# PIC32CX2051BZ66048 register map
Vendor: Microchip Technology; Series: PIC32CXBZ66; File version: 0
CPU: CM4 r0p1, little endian, MPU, FPU, 3 interrupt priority bits, 58 interrupts
Registers are 32-bit, read-write, reset 0x0 unless marked. A register's access mark holds for its fields unless they carry their own. Offsets are from the block's base; [hi:lo] are bit positions; {n}, {i} and the like mark numbered series.

## CRU
Base 0x44000A00
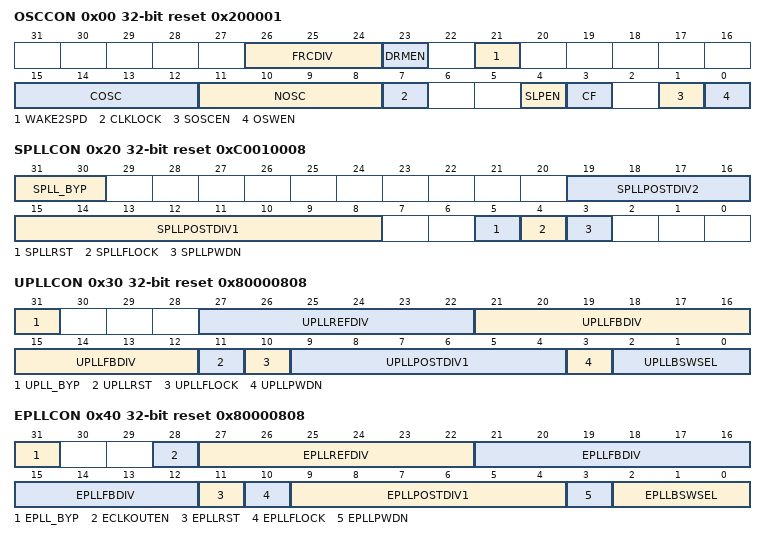
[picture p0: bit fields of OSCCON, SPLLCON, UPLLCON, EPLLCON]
0x00 OSCCON reset 0x200001 — CRU OSCILLATOR CONTROL REGISTER
  [26:24] FRCDIV — Fast RC Clock Divider bits
    0=DIV_1 (FRC Divide by 1); 1=DIV_2 (FRC Divide by 2); 2=DIV_4 (FRC Divide by 4); 3=DIV_8 (FRC Divide by 8); 4=DIV_16 (FRC Divide by 16); 5=DIV_32 (FRC Divide by 32); 6=DIV_64 (FRC Divide by 64); 7=DIV_256 (FRC Divide by 256)
  [23] DRMEN — Enable Dream Mode bit
    1=SLEEP (When the cpu_si_sleep input is asserted and SLPEN = 1, DMA transfer complete causes SLEEP Mode to be entered); 0=NO_EFFECT (DMA transfer has no effect)
  [21] WAKE2SPD — 2-Speed startup enabled in Sleep mode bit
    1=FRC (When the device EXITS Sleep Mode, the sys_clk will be from FRC until the selected clock is ready); 0=SELECTED_CLK (When the device EXITS Sleep Mode, the sys_clk will be from the selected clock.)
  [15:12] COSC — Current Oscillator Selection bits (Read-only)
    0=FRCDIV (Fast RC Oscillator (FRC) divided by OSCCON.FRCDIV (Supports FRC/16 and FRC/1)); 1=SPLL (System PLL (SPLL1 Module) (input clock and divider set by SPLLCON)); 2=POSC (Primary Oscillator- POSC); 3=SOSC (Secondary Oscillator (SOSC)); 4=LPRC (Low Power RC Oscillator (LPRC)); 5=EPLL (Ethernet PLL Clock-2 (EPLL Module) (input clock and divider set by APLLCON)); 6=UPLL (USB PLL Clock (UPLL Module) (input clock and divider set by UPLLCON))
  [11:8] NOSC — New Oscillator Selection bits
    0=FRCDIV (Fast RC Oscillator (FRC) divided by OSCCON.FRCDIV ( Supports FRC/16 and FRC/1)); 1=SPLL (System PLL (SPLL1 Module) (input clock and divider set by SPLLCON)); 2=POSC (Primary Oscillator); 3=SOSC (Secondary Oscillator (SOSC)); 4=LPRC (Low Power RC Oscillator (LPRC)); 5=EPLL (Ethernet PLL Clock-2 (EPLL Module) (input clock and divider set by APLLCON)); 6=UPLL (USB PLL Clock (UPLL Module) (input clock and divider set by UPLLCON))
  [7] CLKLOCK — Clock Lock Enabled bit
    1=LOCKED (All clock and PLL configuration registers are locked. These include OSCCON, OSCTRIM, SPLLCON, UPLLCON, PBxDIV); 0=UNLOCKED (Clock and PLL selection registers are not locked, configurations may be modified)
  [4] SLPEN — Enable SLEEP Mode bit
    1=SLEEP (When a WAIT Instruction is executed device will enter SLEEP Mode); 0=IDLE (When a WAIT instruction is executed device will enter IDLE Mode)
  [3] CF — Clock Fail Detect bit (Read / writable / Clearable by application)
    1=FAIL_DET (FSCM has detected clock failure); 0=NO_FAILDET (FSCM has not detected clock failure)
  [1] SOSCEN — 32 kHz Secondary (LP) Oscillator Enable bit
    1=ON (Enable Secondary Oscillator); 0=OFF (Disable Secondary Oscillator)
  [0] OSWEN — Oscillator Switch Enable bit
    1=SWITCH (Request oscillator switch to selection specified by NOSC[3:0] bits); 0=SWITCH_COMPLETE (Oscillator switch is complete)
0x04 OSCCONCLR
0x08 OSCCONSET
0x0C OSCCONINV
0x10 OSCTUN — CRU OSCILLATOR TRIMMING REGISTER
  [5:0] TUN — Internal Fast RC (FRC) Oscillator Tuning bits
    31=Max (Maximum Frequency); 0=Center Frequency, oscillator is running at calibrated frequency; 32=Min (Minimum Frequency)
0x14 OSCTUNCLR
0x18 OSCTUNSET
0x1C OSCTUNINV
0x20 SPLLCON reset 0xC0010008 — SPLL CONTROL REGISTER
  [31:30] SPLL_BYP — SPLL Clock 2 Source
    0=SPLL3 (SPLL3 (RFPLL) Clock is the clock source for ADC CP Clock Generation.); 3=FRC (FRC is used as clock source for ADC CP Clock Generation.); 2=POSC (POSC is used as clock source for ADC CP Clock Generation.)
  [19:16] SPLLPOSTDIV2 — SPLL Clock 2 Divide Value, 1 to 15
    0=DISABLE; {v}=DIV_{v} (Second post divide by {v}) (v=1..15)
  [15:8] SPLLPOSTDIV1 — SPLL Clock 1 Divide Value, 1 to 255
  [5] SPLLRST — System PLL Reset
    1=ASSERT (Assert the reset to the SPLL); 0=NO_ASSERT (De-assert the reset to the SPLL)
  [4] SPLLFLOCK — System PLL Force Lock
    1=ASSERT (Force the SPLL lock signal to be asserted); 0=NO_ASSERT (Do not force the SPLL lock signal to be asserted)
  [3] SPLLPWDN — PLL Power Down Register bit
    1=PLL_OFF (PLL is powered down); 0=PLL_ON (PLL is active)
0x24 SPLLCONCLR
0x28 SPLLCONSET
0x2C SPLLCONINV
0x30 UPLLCON reset 0x80000808 — UPLL CONTROL REGISTER
  [31] UPLL_BYP — The input clock REF bypasses PLL to PLLOUTx
    1=BYPASS (UPLL Bypass; when this bit is set, the input clock REF bypasses PLL to PLLOUTx); 0=NOT_BYPASS (The input clock dont bypass)
  [27:22] UPLLREFDIV — Reference Frequency Divide in between 1 and 63, value of 0 is unused.
  [21:12] UPLLFBDIV — PLL feedback divider in between 16 and 1023, values of 0 to 15 are unused
  [11] UPLLRST — USB PLL Reset
    1=ASSERT (Assert the reset to the UPLL); 0=NO_ASSERT (De-assert the reset to the UPLL)
  [10] UPLLFLOCK — USB PLL Force Lock
    1=ASSERT (Force the UPLL lock signal to be asserted); 0=NO_ASSERT (Do not force the SPLL lock signal to be asserted)
  [9:4] UPLLPOSTDIV1 — First Post Divide Value in between 1 and 63, value of 0 is unused.
  [3] UPLLPWDN — UPLL Power Down Register bit
    1=PLL_OFF (UPLL is powered down); 0=PLL_ON (UPLL is active)
  [2:0] UPLLBSWSEL — UPLL Bandwidth Select
    1=400KHz (UPLL closed loop bandwith 400KHz); 2=1MHz (UPLL closed loop bandwith 1MHz); 3=2MHz (UPLL closed loop bandwith 2MHz); 4=3MHz (UPLL closed loop bandwith 3MHz)
0x34 UPLLCONCLR
0x38 UPLLCONSET
0x3C UPLLCONINV
0x40 EPLLCON reset 0x80000808 — EPLL CONTROL REGISTER
  [31] EPLL_BYP — The input clock REF bypasses PLL to PLLOUTx
    1=BYPASS (EPLL Bypass; when this bit is set, the input clock REF bypasses PLL to PLLOUTx); 0=NOT_BYPASS (The input clock dont bypass)
  [28] ECLKOUTEN — Ethernet Clock Out pin Enable
    1=Enable (ETH_CLK_OUT Pin is enabled); 0=Disable (ETH_CLK_OUT Pin is disabled)
  [27:22] EPLLREFDIV — Reference Frequency Divide in between 1 and 63, value of 0 is unused.
  [21:12] EPLLFBDIV — PLL feedback divider in between 16 and 1023, values of 0 to 15 are unused
  [11] EPLLRST — Ethernet PLL Reset
    1=ASSERT (Assert the reset to the EPLL); 0=NO_ASSERT (De-assert the reset to the EPLL)
  [10] EPLLFLOCK — Ethernet PLL Force Lock
    1=ASSERT (Force the EPLL lock signal to be asserted); 0=NO_ASSERT (Do not force the SPLL lock signal to be asserted)
  [9:4] EPLLPOSTDIV1 — First Post Divide Value in between 1 and 63, value of 0 is unused.
  [3] EPLLPWDN — EPLL Power Down Register bit
    1=PLL_OFF (EPLL is powered down); 0=PLL_ON (EPLL is active)
  [2:0] EPLLBSWSEL — EPLL Bandwidth Select
    1=400KHz (EPLL closed loop bandwith 400KHz); 2=1MHz (EPLL closed loop bandwith 1MHz); 3=2MHz (EPLL closed loop bandwith 2MHz); 4=3MHz (EPLL closed loop bandwith 3MHz)
0x44 EPLLCONCLR
0x48 EPLLCONSET
0x4C EPLLCONINV
0x50 APLLCON — APLL CONTROL REGISTER
  [5:0] EPLLPOSTIDIV2 — EPLL Post Divider bits for controlling second PLL clock output, value of 0 is unused.
0x54 APLLCONCLR
0x58 APLLCONSET
0x5C APLLCONINV
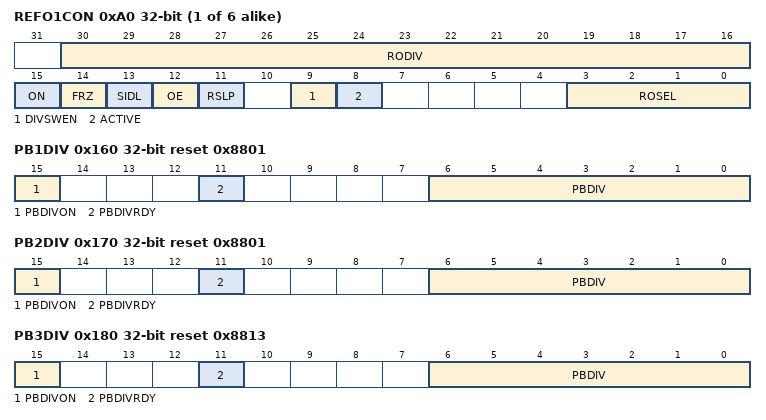
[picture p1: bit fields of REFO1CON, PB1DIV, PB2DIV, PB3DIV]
{0x80+0x20*i} REFO{i}CON (i=1..6) — REFERENCE OSCILLATOR {i} CONTROL REGISTER
  [30:16] RODIV — Reference Clock Divider bits
    0x7FFF=65K (REFO{i} clock is Base clock frequency divided by 65,534 (32,767 *2)); 2=REFO{i} clock is Base clock frequency divided by 4 (2*2); 1=REFO{i} clock is Base clock frequency divided by 2 (1*2); 0=NONE (REFO{i} clock is same frequency as Base clock (no divider))
  [15] ON — Output Enable bit
    1=ON (Reference Oscillator Module enabled); 0=OFF (Reference Oscillator Module disabled)
  [14] FRZ — Freeze in Debug mode bit
    1=FRZ (When emulator is in Debug mode, module freezes operation); 0=NO_FRZ (When emulator is in Debug mode, module continues operation)
  [13] SIDL — Peripheral Stop in Idle Mode bit
    1=SIDL (Discontinue module operation when device enters Idle mode); 0=NO_SIDL (Continue module operation in Idle mode)
  [12] OE — Reference Clock Output Enable bit
    1=REFO{i}_OE (Reference clock is driven out on REFO{i} pin); 0=NO_REFO{i}_OE (Reference clock is not driven out on REFO{i} pin.)
  [11] RSLP — Reference Oscillator Run in Sleep bit
    1=RSLP (Reference Oscillator output continues to run in Sleep); 0=NO_RSLP (Reference Oscillator output is disabled in Sleep)
  [9] DIVSWEN — Clock RODIV/ROTRIM switch enabled.
    1=SWINPROGRESS (Clock Divider Switching currently in progress.); 0=SWCOMPLETE (Clock Divider Switch has completed.)
  [8] ACTIVE — Reference Clock Request Status bit
    1=ACTIVE (Reference clock request is active (User should not update this REFOCON register)); 0=NOT_ACTIVE (Reference clock request is not active (User can update this REFOCON register))
  [3:0] ROSEL — Reference Clock Source Select bits
    11=REFCLKI (REFI Pin); 10=SYSCLK (System clock (reference clock reflects any device clock switching)); 9=PBCLK1 (Peripheral clock 1 (reference clock reflects any peripheral clock switching)); 8=EPLL1 (Ethernet PLL1 (Clock-1)); 7=SPLL3 (System PLL3 (Clock-3)); 6=USBPLL; 5=EPLL2 (Ethernet PLL2 (Clock-2)); 4=LPRC; 3=SOSC; 2=POSC; 1=SPLL1 (System PLL1 (Clock-1)); 0=FRC
{0x84+0x20*i} REFO{i}CONCLR (i=1..6)
{0x88+0x20*i} REFO{i}CONSET (i=1..6)
{0x8C+0x20*i} REFO{i}CONINV (i=1..6)
{0x90+0x20*i} REFO{i}TRIM (i=1..6) — REFERENCE OSCILLATOR {i} TRIM REGISTER
  [31:23] ROTRIM — Trim bits - Provides fractional additive to RODIV value for 1/2 period of REFO1 clock
    0=ZERO (0/512 (0.0) divisor added to RODIV value); 1=1/512 (0.001953125) divisor added to RODIV value; 2=2/512 (0.00390625) divisor added to RODIV value; 0x100=256/512 (0.5000) divisor added to RODIV value; 0x1FF=511/512 (0.998046875) divisor added to RODIV value
{0x94+0x20*i} REFO{i}TRIMCLR (i=1..6)
{0x98+0x20*i} REFO{i}TRIMSET (i=1..6)
{0x9C+0x20*i} REFO{i}TRIMINV (i=1..6)
0x160 PB1DIV reset 0x8801 — PB1 CLOCK DIVISOR CONTROL REGISTER
  [15] PBDIVON — Output Enable bit
    1=PB1ON (PB1 Output clock is enabled); 0=PB1OFF (PB1 Output clock is disabled)
  [11] PBDIVRDY — PB1 Peripheral Clock Divisor Ready
    1=PB1RDY (Indicates the PB clock divisor logic is not switching divisors and the PB1DIV may be written.); 0=NOT_PB1RDY (Indicates the PB clock divisor logic is currently switching values and the PB1DIV cannot be written.)
  [6:0] PBDIV — PB1 Peripheral Clock Divisor Control value
    0=DIV1 (Divide by 1 PB1 Clock same frequency as sys_clk); 1=DIV2 (Divide by 2 PB1 Clock is 1/2 of sys_clk); 2=DIV3 (Divide by 3 PB1 Clock is 1/3 of sys_clk); 15=DIV16 (Divide by 16 PB1 Clock is 1/16 of sys_clk); 16=DIV17 (Divide by 17 PB1 Clock is 1/17 of sys_clk); 126=DIV127 (Divide by 127 PB1 Clock is 1/127 of sys_clk); 127=DIV128 (Divide by 128 PB1 Clock is 1/128 of sys_clk)
{0x154+0x10*i} PB{i}DIVCLR (i=1..5)
{0x158+0x10*i} PB{i}DIVSET (i=1..5)
{0x15C+0x10*i} PB{i}DIVINV (i=1..5)
0x170 PB2DIV reset 0x8801 — PB2 CLOCK DIVISOR CONTROL REGISTER
  [15] PBDIVON — Output Enable bit
    1=PB2ON (PB2 Output clock is enabled); 0=PB2OFF (PB2 Output clock is disabled)
  [11] PBDIVRDY — PB2 Peripheral Clock Divisor Ready
    1=PB2RDY (Indicates the PB clock divisor logic is not switching divisors and the PB2DIV may be written.); 0=NOT_PB2RDY (Indicates the PB clock divisor logic is currently switching values and the PB2DIV cannot be written.)
  [6:0] PBDIV — PB2 Peripheral Clock Divisor Control value
    0=DIV1 (Divide by 1 PB2 Clock same frequency as sys_clk); 1=DIV2 (Divide by 2 PB2 Clock is 1/2 of sys_clk); 2=DIV3 (Divide by 3 PB2 Clock is 1/3 of sys_clk); 15=DIV16 (Divide by 16 PB2 Clock is 1/16 of sys_clk); 16=DIV17 (Divide by 17 PB2 Clock is 1/17 of sys_clk); 126=DIV127 (Divide by 127 PB2 Clock is 1/127 of sys_clk); 127=DIV128 (Divide by 128 PB2 Clock is 1/128 of sys_clk)
0x180 PB3DIV reset 0x8813 — PB3 CLOCK DIVISOR CONTROL REGISTER
  [15] PBDIVON — Output Enable bit
    1=PB3ON (PB3 Output clock is enabled); 0=PB3OFF (PB3 Output clock is disabled)
  [11] PBDIVRDY — PB3 Peripheral Clock Divisor Ready
    1=PB3RDY (Indicates the PB clock divisor logic is not switching divisors and the PB3DIV may be written.); 0=NOT_PB3RDY (Indicates the PB clock divisor logic is currently switching values and the PB3DIV cannot be written.)
  [6:0] PBDIV — PB3 Peripheral Clock Divisor Control value
    0=DIV1 (Divide by 1 PB3 Clock same frequency as sys_clk); 1=DIV2 (Divide by 2 PB3 Clock is 1/2 of sys_clk); 2=DIV3 (Divide by 3 PB3 Clock is 1/3 of sys_clk); 15=DIV16 (Divide by 16 PB3 Clock is 1/16 of sys_clk); 16=DIV17 (Divide by 17 PB3 Clock is 1/17 of sys_clk); 126=DIV127 (Divide by 127 PB3 Clock is 1/127 of sys_clk); 127=DIV128 (Divide by 128 PB3 Clock is 1/128 of sys_clk)
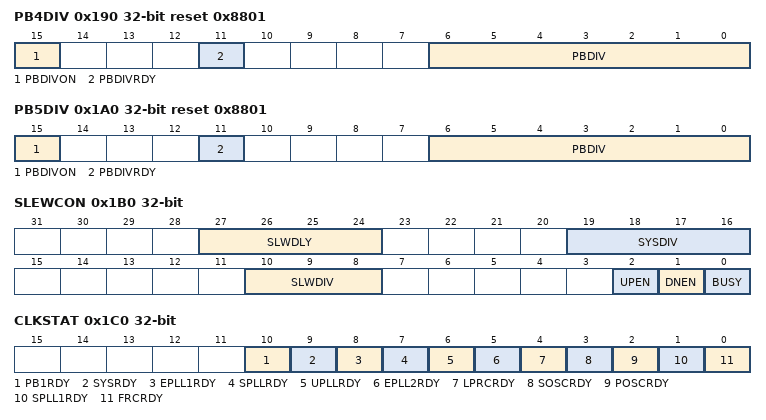
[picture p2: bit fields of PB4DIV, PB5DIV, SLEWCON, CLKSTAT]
0x190 PB4DIV reset 0x8801 — PB4 CLOCK DIVISOR CONTROL REGISTER
  [15] PBDIVON — Output Enable bit
    1=PB4ON (PB4 Output clock is enabled); 0=PB4OFF (PB4 Output clock is disabled)
  [11] PBDIVRDY — PB4 Peripheral Clock Divisor Ready
    1=PB4RDY (Indicates the PB clock divisor logic is not switching divisors and the PB4DIV may be written.); 0=NOT_PB4RDY (Indicates the PB clock divisor logic is currently switching values and the PB4DIV cannot be written.)
  [6:0] PBDIV — PB4 Peripheral Clock Divisor Control value
    0=DIV1 (Divide by 1 PB4 Clock same frequency as sys_clk); 1=DIV2 (Divide by 2 PB4 Clock is 1/2 of sys_clk); 2=DIV3 (Divide by 3 PB4 Clock is 1/3 of sys_clk); 15=DIV16 (Divide by 16 PB4 Clock is 1/16 of sys_clk); 16=DIV17 (Divide by 17 PB4 Clock is 1/17 of sys_clk); 126=DIV127 (Divide by 127 PB4 Clock is 1/127 of sys_clk); 127=DIV128 (Divide by 128 PB4 Clock is 1/128 of sys_clk)
0x1A0 PB5DIV reset 0x8801 — PB5 CLOCK DIVISOR CONTROL REGISTER
  [15] PBDIVON — Output Enable bit
    1=PB5ON (PB5 Output clock is enabled); 0=PB5OFF (PB5 Output clock is disabled)
  [11] PBDIVRDY — PB5 Peripheral Clock Divisor Ready
    1=PB5RDY (Indicates the PB clock divisor logic is not switching divisors and the PB5DIV may be written.); 0=NOT_PB5RDY (Indicates the PB clock divisor logic is currently switching values and the PB5DIV cannot be written.)
  [6:0] PBDIV — PB5 Peripheral Clock Divisor Control value
    0=DIV1 (Divide by 1 PB5 Clock same frequency as sys_clk); 1=DIV2 (Divide by 2 PB5 Clock is 1/2 of sys_clk); 2=DIV3 (Divide by 3 PB5 Clock is 1/3 of sys_clk); 15=DIV16 (Divide by 16 PB5 Clock is 1/16 of sys_clk); 16=DIV17 (Divide by 17 PB5 Clock is 1/17 of sys_clk); 126=DIV127 (Divide by 127 PB5 Clock is 1/127 of sys_clk); 127=DIV128 (Divide by 128 PB5 Clock is 1/128 of sys_clk)
0x1B0 SLEWCON — SLEW RATE CONTROL FOR CLOCK SWITCHING REGISTER
  [27:24] SLWDLY — Number of clocks generated at each slew step for a clock switch
    0=1 clock will be generated at each slew step; {v}={v+1} clocks will be generated at each slew step (v=1..15)
  [19:16] SYSDIV — PBx Peripheral Clock Divisor Control value
    0=DIV1 (Divide by 1- sys_clk_out same frequency as sys_clk source - Default); {v}=DIV{v+1} (Divide by {v+1}- sys_clk_out is 1/{v+1} of sys_clk source) (v=1..15)
  [10:8] SLWDIV — Divisor steps used when doing slewed clock switches
    0=NONE (No Divisor used); 1=Divide by 2, then no divisor; 2=4to2 (Divide by 4, then by 2, then no divisor); 3=8to2 (Divide by 8, then by 4, then by 2, then no divisor); 4=16to2 (Divide by 16, then by 8, then by 4, then by 2, then no divisor); 5=32to2 (Divide by 32, then by 16, then by 8, then by 4, then by 2, then no divisor); 6=64to2 (Divide by 64, then by 32, then by 16, then by 8, then by 4, then by 2, then no divisor); 7=128to2 (Divide by 128, then by 64, then by 32, then by 16, then by 8, then by 4, then by 2, then no divisor)
  [2] UPEN — Clock slew enable for switching up to faster clocks
    0=DISABLED (Clock Slewing disabled); 1=ENABLED (Clock Slewing enabled on a clock switch OR exit from SLEEP)
  [1] DNEN — Clock slew enable for switching down to slower clocks
    0=DISABLED (Clock Slewing disabled); 1=ENABLED (Clock Slewing enabled on a clock switch)
  [0] BUSY — Clock Switch Slewing Active Status Bit - Read-Only
    0=FINAL (Clock Switch has reached its final value); 1=BUSY (Clock frequency is being actively Slewed)
0x1B4 SLEWCONCLR
0x1B8 SLEWCONSET
0x1BC SLEWCONINV
0x1C0 CLKSTAT — CLOCK STATUS REGISTER
  [10] PB1RDY — PB1 Clock Ready Status value
    0=NOTRDY (PB1 clock is not stable and not ready); 1=RDY (PB1 clock is stable and ready)
  [9] SYSRDY — System Clock Ready Status value
    0=NOTRDY (System clock is not stable and not ready); 1=RDY (System clock is stable and ready)
  [8] EPLL1RDY — Ethernet PLL1 Ready Status value
    0=NOTRDY (EPLL1 is not stable and not ready); 1=RDY (EPLL1 is stable and ready)
  [7] SPLLRDY — System PLL Ready Status value
    0=NOTRDY (SPLL is not stable and not ready); 1=RDY (SPLL is stable and ready)
  [6] UPLLRDY — USB PLL Ready Status value
    0=NOTRDY (UPLL is not stable and not ready); 1=RDY (UPLL is stable and ready)
  [5] EPLL2RDY — Ethernet PLL2 Ready Status value
    0=NOTRDY (EPLL2 is not stable and not ready); 1=RDY (EPLL2 is stable and ready)
  [4] LPRCRDY — LPRC Ready Status value
    0=NOTRDY (LPRC is not stable and not ready); 1=RDY (LPRC is stable and ready)
  [3] SOSCRDY — SOSC Ready Status value
    0=NOTRDY (SOSC is not stable and not ready); 1=RDY (SOSC is stable and ready)
  [2] POSCRDY — Primary Oscillator Ready Status value
    0=NOTRDY (POSC is not stable and not ready); 1=RDY (POSC is stable and ready)
  [1] SPLL1RDY — System PLL1 Ready Status value
    0=NOTRDY (SPLL1 Primary Output is not stable and not ready); 1=RDY (SPLL1 Primary Output is stable and ready)
  [0] FRCRDY — FRC Ready Status value
    0=NOTRDY (FRC is not stable and not ready); 1=RDY (FRC is stable and ready)
0x1C4 CLKSTATCLR
0x1C8 CLKSTATSET
0x1CC CLKSTATINV
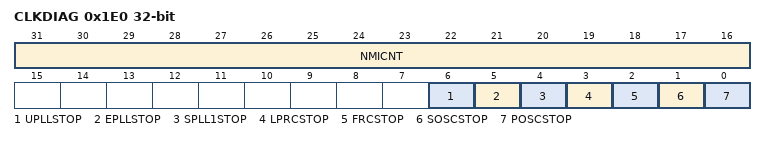
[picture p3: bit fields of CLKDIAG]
0x1E0 CLKDIAG — USER CLK DIAGNOSTICS CONTROL REGISTER
  [31:16] NMICNT — NMI Counter value
  [6] UPLLSTOP — UPLL Clock Stop Control value
    0=NORM (UPLL clock source runs as normal); 1=STOP (UPLL clock source is stopped)
  [5] EPLLSTOP — EPLL Clock Stop Control value
    0=NORM (EPLL clock source runs as normal); 1=STOP (EPLL clock source is stopped)
  [4] SPLL1STOP — SPLL1 Clock Stop Control value
    0=NORM (SPLL1 clock source runs as normal); 1=STOP (SPLL1 clock source is stopped)
  [3] LPRCSTOP — LPRC Clock Stop Control value
    0=NORM (LPRC clock source runs as normal); 1=STOP (LPRC clock source is stopped)
  [2] FRCSTOP — FRC Clock Stop Control value
    0=NORM (FRC clock source runs as normal); 1=STOP (FRC clock source is stopped)
  [1] SOSCSTOP — SOSC Clock Stop Control value
    0=NORM (SOSC clock source runs as normal); 1=STOP (SOSC clock source is stopped)
  [0] POSCSTOP — POSC Clock Stop Control value
    0=NORM (POSC clock source runs as normal); 1=STOP (POSC clock source is stopped)
0x1E4 CLKDIAGCLR
0x1E8 CLKDIAGSET
0x1EC CLKDIAGINV
